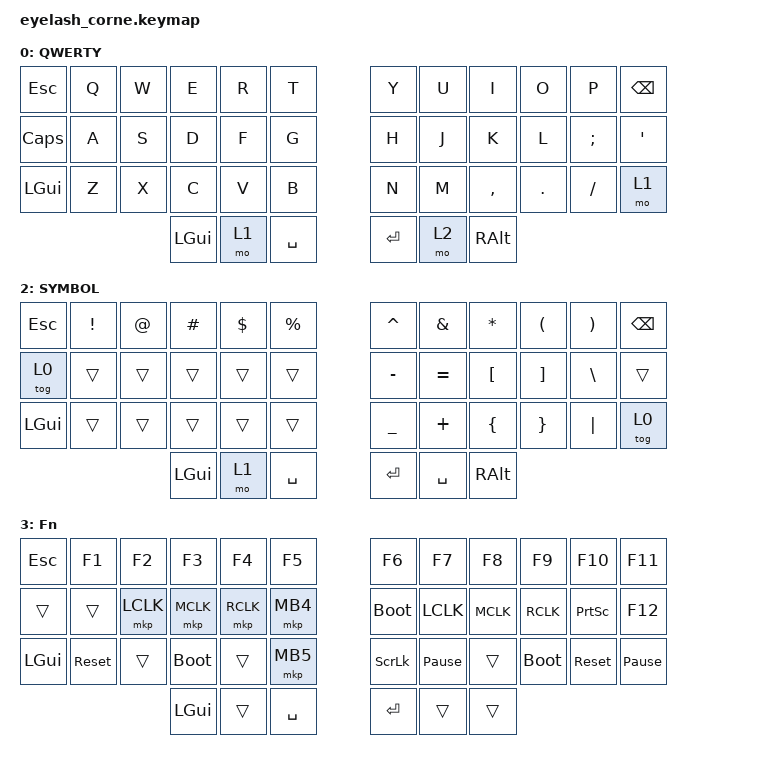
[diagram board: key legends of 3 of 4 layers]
#include <behaviors.dtsi>
#include <dt-bindings/zmk/bt.h>
#include <dt-bindings/zmk/keys.h>
#include <dt-bindings/zmk/mouse.h>
#include <dt-bindings/zmk/outputs.h>
#include <dt-bindings/zmk/rgb.h>

/ {
    behaviors {
        td0: td0 {
            compatible = "zmk,behavior-tap-dance";
            #binding-cells = <0>;
            bindings = <&kp LEFT_SHIFT>, <&kp CAPS>;
        };
    };

    rgb_encoder: rgb_encoder {
        compatible = "zmk,behavior-sensor-rotate";
        #sensor-binding-cells = <0>;
        bindings = <&rgb_ug RGB_BRI>, <&rgb_ug RGB_BRD>;
    };

    keymap {
        compatible = "zmk,keymap";

        default_layer {
            display-name = "QWERTY";

            bindings = <
                &kp ESC       &kp Q      &kp W      &kp E      &kp R      &kp T         &kp Y     &kp U      &kp I     &kp O     &kp P    &kp BSPC
                &kp CAPS      &kp A      &kp S      &kp D      &kp F      &kp G         &kp H     &kp J      &kp K     &kp L     &kp SEMI &kp SQT
                &kp LGUI      &kp Z      &kp X      &kp C      &kp V      &kp B         &kp N     &kp M      &kp COMMA &kp DOT   &kp FSLH &mo 1
                                &kp LGUI  &mo 1      &kp SPACE  &kp RET    &mo 2         &kp RALT
            >;

            sensor-bindings = <&inc_dec_kp C_VOLUME_UP C_VOLUME_DOWN>;
        };

        lower_layer {
            display-name = "NUMBER";

            bindings = <
                &kp ESC       &kp N1     &kp N2     &kp N3     &kp N4     &kp N5       &kp N6     &kp N7     &kp N8     &kp N9     &kp N0 &kp BSPC
                &bt BT_CLR    &bt BT_SEL 0 &bt BT_SEL 1 &bt BT_SEL 2 &bt BT_SEL 3 &bt BT_SEL 4   &trans     &trans     &kp UP    &trans   &tog 0
                &kp LGUI      &trans     &trans     &trans     &trans     &trans       &trans     &trans     &trans     &trans     &trans &mo 2
                                &kp LGUI   &trans     &kp SPACE  &kp RET    &kp DOWN     &kp RALT
            >;

            sensor-bindings = <&inc_dec_kp PG_UP PG_DN>;
        };

        raise_layer {
            display-name = "SYMBOL";

            bindings = <
                &kp ESC       &kp EXCL   &kp AT     &kp HASH   &kp DLLR   &kp PRCNT     &kp CARET  &kp AMPS   &kp ASTRK  &kp LPAR   &kp RPAR &kp BSPC
                &tog 0        &trans     &trans     &trans     &trans     &trans       &kp MINUS  &kp EQUAL  &kp LBKT   &kp RBKT   &kp BSLH &trans
                &kp LGUI      &trans     &trans     &trans     &trans     &trans       &kp UNDER  &kp PLUS   &kp LBRC   &kp RBRC   &kp PIPE &tog 0
                                &kp LGUI   &mo 1      &kp SPACE  &kp RET    &kp SPACE    &kp RALT
            >;

            sensor-bindings = <&inc_dec_kp PG_UP PG_DN>;
        };

        layer_3 {
            display-name = "Fn";

            bindings = <
                &kp ESC       &kp F1     &kp F2     &kp F3     &kp F4     &kp F5       &kp F6     &kp F7     &kp F8     &kp F9     &kp F10    &kp F11
                &trans        &trans     &mkp LCLK  &mkp MCLK  &mkp RCLK  &mkp MB4     &bootloader &kp LCLK  &kp MCLK  &kp RCLK   &kp PRINTSCREEN &kp F12
                &kp LGUI      &sys_reset &trans     &bootloader &trans    &mkp MB5     &kp SCROLLLOCK &kp PAUSE_BREAK &trans     &bootloader  &sys_reset &kp PAUSE_BREAK
                                &kp LGUI   &trans     &kp SPACE  &kp RET    &trans       &trans
            >;

            sensor-bindings = <&rgb_encoder>;
        };
    };
};
